AUTOSAR XML (schema 4-0-3)
standard types defined: Boolean, UInt16, UInt32, UInt8
package /AUTOSAR_Platform/DataConstrs
  range DC_Boolean: raw 0..1
  range DC_UInt16: raw 0..65535
  range DC_UInt8: raw 0..255
package /PATAC/MSM/ComponentTypes
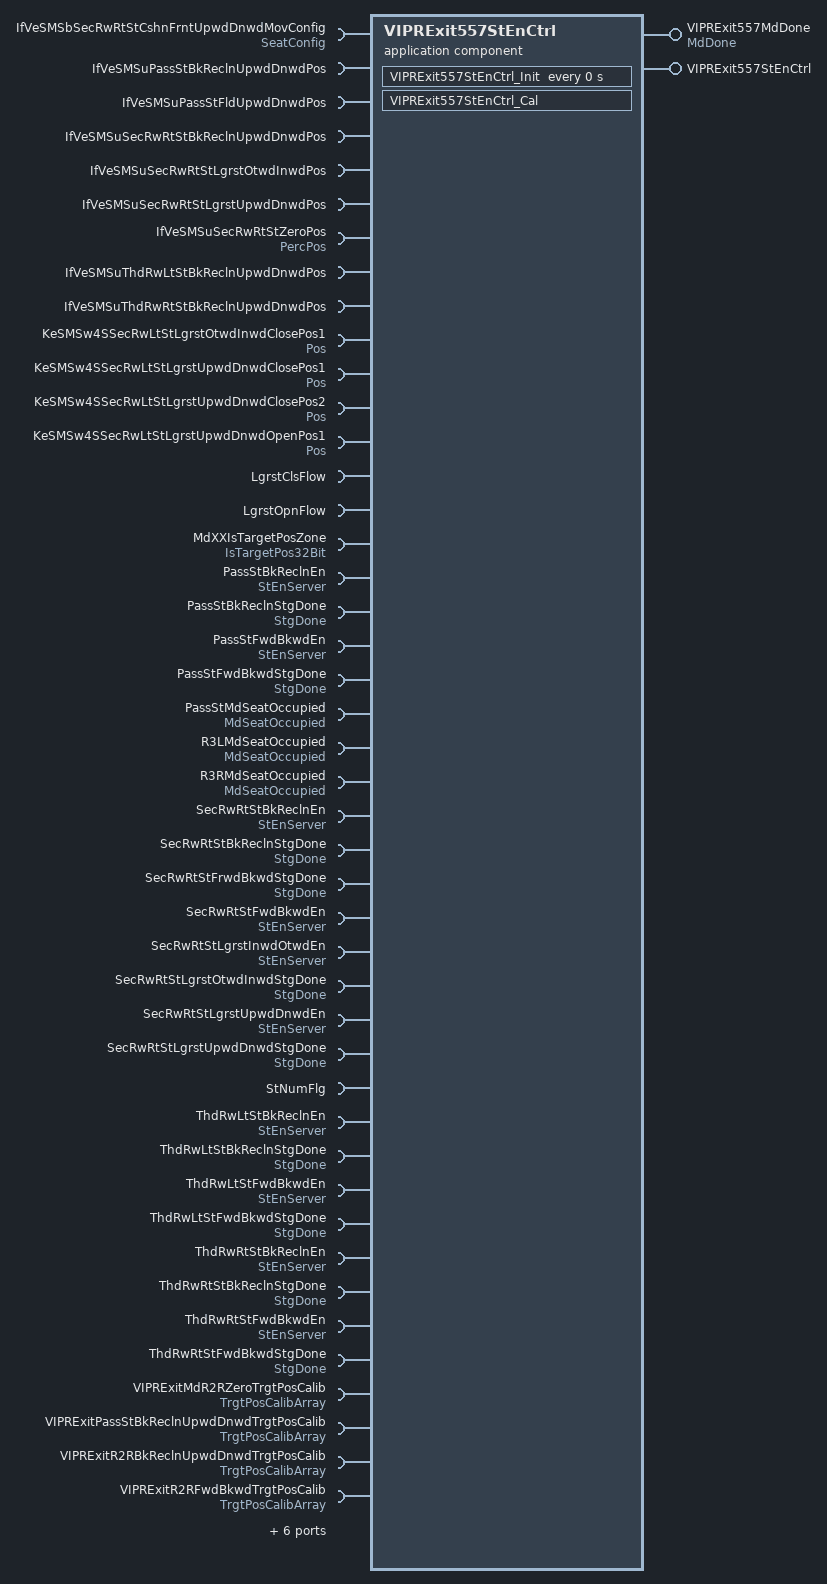
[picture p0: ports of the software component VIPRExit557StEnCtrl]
  application sw component type VIPRExit557StEnCtrl
    provide port VIPRExit557MdDone: nonqueued-sender-com-spec{data-element=MdDone/Val, init-value=0}, provided-interface=MdDone
    provide port VIPRExit557StEnCtrl: server-com-spec{operation=VIPRExit557StEnCtrl/Cal, queue-length=1}, provided-interface=VIPRExit557StEnCtrl
    50 x require port:
      IfVeSMSbSecRwRtStCshnFrntUpwdDnwdMovConfig: nonqueued-receiver-com-spec{data-element=SeatConfig/Val, filter=data-filter-type=ALWAYS, init-value=0}, required-interface=SeatConfig
      IfVeSMSuPassStBkReclnUpwdDnwdPos: nonqueued-receiver-com-spec{data-element=IfVeSMSuPassStBkReclnUpwdDnwdPos/Val, filter=data-filter-type=ALWAYS, init-value=0}, required-interface=IfVeSMSuPassStBkReclnUpwdDnwdPos
      IfVeSMSuPassStFldUpwdDnwdPos: nonqueued-receiver-com-spec{data-element=IfVeSMSuPassStFldUpwdDnwdPos/Val, filter=data-filter-type=ALWAYS, init-value=0}, required-interface=IfVeSMSuPassStFldUpwdDnwdPos
      IfVeSMSuSecRwRtStBkReclnUpwdDnwdPos: nonqueued-receiver-com-spec{data-element=IfVeSMSuSecRwRtStBkReclnUpwdDnwdPos/Val, filter=data-filter-type=ALWAYS, init-value=0}, required-interface=IfVeSMSuSecRwRtStBkReclnUpwdDnwdPos
      IfVeSMSuSecRwRtStLgrstOtwdInwdPos: nonqueued-receiver-com-spec{data-element=IfVeSMSuSecRwRtStLgrstOtwdInwdPos/Val, filter=data-filter-type=ALWAYS, init-value=0}, required-interface=IfVeSMSuSecRwRtStLgrstOtwdInwdPos
      IfVeSMSuSecRwRtStLgrstUpwdDnwdPos: nonqueued-receiver-com-spec{data-element=IfVeSMSuSecRwRtStLgrstUpwdDnwdPos/Val, filter=data-filter-type=ALWAYS, init-value=0}, required-interface=IfVeSMSuSecRwRtStLgrstUpwdDnwdPos
      IfVeSMSuSecRwRtStZeroPos: nonqueued-receiver-com-spec{data-element=PercPos/Val, filter=data-filter-type=ALWAYS, init-value=0}, required-interface=PercPos
      IfVeSMSuThdRwLtStBkReclnUpwdDnwdPos: nonqueued-receiver-com-spec{data-element=IfVeSMSuThdRwLtStBkReclnUpwdDnwdPos/Val, filter=data-filter-type=ALWAYS, init-value=0}, required-interface=IfVeSMSuThdRwLtStBkReclnUpwdDnwdPos
      IfVeSMSuThdRwRtStBkReclnUpwdDnwdPos: nonqueued-receiver-com-spec{data-element=IfVeSMSuThdRwRtStBkReclnUpwdDnwdPos/Val, filter=data-filter-type=ALWAYS, init-value=0}, required-interface=IfVeSMSuThdRwRtStBkReclnUpwdDnwdPos
      KeSMSw4SSecRwLtStLgrstOtwdInwdClosePos1: parameter-require-com-spec{init-value=0, parameter=Val}, required-interface=Pos
      KeSMSw4SSecRwLtStLgrstUpwdDnwdClosePos1: parameter-require-com-spec{init-value=0, parameter=Val}, required-interface=Pos
      KeSMSw4SSecRwLtStLgrstUpwdDnwdClosePos2: parameter-require-com-spec{init-value=0, parameter=Val}, required-interface=Pos
      KeSMSw4SSecRwLtStLgrstUpwdDnwdOpenPos1: parameter-require-com-spec{init-value=0, parameter=Val}, required-interface=Pos
      LgrstClsFlow: client-com-spec=LgrstClsFlow/Cal, required-interface=LgrstClsFlow
      LgrstOpnFlow: client-com-spec=LgrstOpnFlow/Cal, required-interface=LgrstOpnFlow
      MdXXIsTargetPosZone: nonqueued-receiver-com-spec{data-element=IsTargetPos32Bit/Val, filter=data-filter-type=ALWAYS, init-value=0}, required-interface=IsTargetPos32Bit
      PassStBkReclnEn: required-com-specs=[Clear, Get, Set], required-interface=StEnServer
      PassStBkReclnStgDone: nonqueued-receiver-com-spec{data-element=StgDone/Val, filter=data-filter-type=ALWAYS, init-value=0}, required-interface=StgDone
      PassStFwdBkwdEn: required-com-specs=[Clear, Get, Set], required-interface=StEnServer
      PassStFwdBkwdStgDone: nonqueued-receiver-com-spec{data-element=StgDone/Val, filter=data-filter-type=ALWAYS, init-value=0}, required-interface=StgDone
      PassStMdSeatOccupied: nonqueued-receiver-com-spec{data-element=MdSeatOccupied/Val, filter=data-filter-type=ALWAYS, init-value=0}, required-interface=MdSeatOccupied
      R3LMdSeatOccupied: nonqueued-receiver-com-spec{data-element=MdSeatOccupied/Val, filter=data-filter-type=ALWAYS, init-value=0}, required-interface=MdSeatOccupied
      R3RMdSeatOccupied: nonqueued-receiver-com-spec{data-element=MdSeatOccupied/Val, filter=data-filter-type=ALWAYS, init-value=0}, required-interface=MdSeatOccupied
      SecRwRtStBkReclnEn: required-com-specs=[Clear, Get, Set], required-interface=StEnServer
      SecRwRtStBkReclnStgDone: nonqueued-receiver-com-spec{data-element=StgDone/Val, filter=data-filter-type=ALWAYS, init-value=0}, required-interface=StgDone
      SecRwRtStFrwdBkwdStgDone: nonqueued-receiver-com-spec{data-element=StgDone/Val, filter=data-filter-type=ALWAYS, init-value=0}, required-interface=StgDone
      SecRwRtStFwdBkwdEn: required-com-specs=[Clear, Get, Set], required-interface=StEnServer
      SecRwRtStLgrstInwdOtwdEn: required-com-specs=[Clear, Get, Set], required-interface=StEnServer
      SecRwRtStLgrstOtwdInwdStgDone: nonqueued-receiver-com-spec{data-element=StgDone/Val, filter=data-filter-type=ALWAYS, init-value=0}, required-interface=StgDone
      SecRwRtStLgrstUpwdDnwdEn: required-com-specs=[Clear, Get, Set], required-interface=StEnServer
      SecRwRtStLgrstUpwdDnwdStgDone: nonqueued-receiver-com-spec{data-element=StgDone/Val, filter=data-filter-type=ALWAYS, init-value=0}, required-interface=StgDone
      StNumFlg: required-interface=StNumFlg
        required-com-specs:
          data-element=Is4s, filter=data-filter-type=ALWAYS, init-value=0
          data-element=Is6s, filter=data-filter-type=ALWAYS, init-value=0
          data-element=Is6s7s, filter=data-filter-type=ALWAYS, init-value=0
          data-element=Is7s, filter=data-filter-type=ALWAYS, init-value=0
      ThdRwLtStBkReclnEn: required-com-specs=[Clear, Get, Set], required-interface=StEnServer
      ThdRwLtStBkReclnStgDone: nonqueued-receiver-com-spec{data-element=StgDone/Val, filter=data-filter-type=ALWAYS, init-value=0}, required-interface=StgDone
      ThdRwLtStFwdBkwdEn: required-com-specs=[Clear, Get, Set], required-interface=StEnServer
      ThdRwLtStFwdBkwdStgDone: nonqueued-receiver-com-spec{data-element=StgDone/Val, filter=data-filter-type=ALWAYS, init-value=0}, required-interface=StgDone
      ThdRwRtStBkReclnEn: required-com-specs=[Clear, Get, Set], required-interface=StEnServer
      ThdRwRtStBkReclnStgDone: nonqueued-receiver-com-spec{data-element=StgDone/Val, filter=data-filter-type=ALWAYS, init-value=0}, required-interface=StgDone
      ThdRwRtStFwdBkwdEn: required-com-specs=[Clear, Get, Set], required-interface=StEnServer
      ThdRwRtStFwdBkwdStgDone: nonqueued-receiver-com-spec{data-element=StgDone/Val, filter=data-filter-type=ALWAYS, init-value=0}, required-interface=StgDone
      VIPRExitMdR2RZeroTrgtPosCalib: nonqueued-receiver-com-spec{data-element=TrgtPosArray, filter=data-filter-type=ALWAYS, init-value=[4095, 4095, 4095]}, required-interface=TrgtPosCalibArray
      VIPRExitPassStBkReclnUpwdDnwdTrgtPosCalib: nonqueued-receiver-com-spec{data-element=TrgtPosArray, filter=data-filter-type=ALWAYS, init-value=[4095, 4095, 4095]}, required-interface=TrgtPosCalibArray
      VIPRExitR2RBkReclnUpwdDnwdTrgtPosCalib: nonqueued-receiver-com-spec{data-element=TrgtPosArray, filter=data-filter-type=ALWAYS, init-value=[4095, 4095, 4095]}, required-interface=TrgtPosCalibArray
      VIPRExitR2RFwdBkwdTrgtPosCalib: nonqueued-receiver-com-spec{data-element=TrgtPosArray, filter=data-filter-type=ALWAYS, init-value=[4095, 4095, 4095]}, required-interface=TrgtPosCalibArray
      VIPRExitR2RLgrstInwdOtwdTrgtPosCalib: nonqueued-receiver-com-spec{data-element=TrgtPosArray, filter=data-filter-type=ALWAYS, init-value=[4095, 4095, 4095]}, required-interface=TrgtPosCalibArray
      VIPRExitR2RLgrstUpwdDnwdTrgtPosCalib: nonqueued-receiver-com-spec{data-element=TrgtPosArray, filter=data-filter-type=ALWAYS, init-value=[4095, 4095, 4095]}, required-interface=TrgtPosCalibArray
      VIPRExitR3LBkReclnUpwdDnwdTrgtPosCalib: nonqueued-receiver-com-spec{data-element=TrgtPosArray, filter=data-filter-type=ALWAYS, init-value=[4095, 4095, 4095]}, required-interface=TrgtPosCalibArray
      VIPRExitR3RBkReclnUpwdDnwdTrgtPosCalib: nonqueued-receiver-com-spec{data-element=TrgtPosArray, filter=data-filter-type=ALWAYS, init-value=[4095, 4095, 4095]}, required-interface=TrgtPosCalibArray
      ZeroREn: required-com-specs=[Clear, Get, Set], required-interface=StEnServer
      ZeroRStgDone: nonqueued-receiver-com-spec{data-element=StgDone/Val, filter=data-filter-type=ALWAYS, init-value=0}, required-interface=StgDone
    behavior VIPRExit557StEnCtrl_InternalBehavior
      operation invoked event OIT_VIPRExit557StEnCtrl_Cal_VIPRExit557StEnCtrl_Cal: start-on-event=VIPRExit557StEnCtrl_Cal, operation=VIPRExit557StEnCtrl.Cal
      timing event VIPRExit557StEnCtrl_InitEvent: start-on-event=VIPRExit557StEnCtrl_Init, period=0
      runnable VIPRExit557StEnCtrl_Cal
        data-receive-point-by-arguments:
          36 x access:
            REC_IfVeSMSbSecRwRtStCshnFrntUpwdDnwdMovConfig_Val: accessed-variable=IfVeSMSbSecRwRtStCshnFrntUpwdDnwdMovConfig.Val
            REC_IfVeSMSuPassStBkReclnUpwdDnwdPos_Val: accessed-variable=IfVeSMSuPassStBkReclnUpwdDnwdPos.Val
            REC_IfVeSMSuPassStFldUpwdDnwdPos_Val: accessed-variable=IfVeSMSuPassStFldUpwdDnwdPos.Val
            REC_IfVeSMSuSecRwRtStBkReclnUpwdDnwdPos_Val: accessed-variable=IfVeSMSuSecRwRtStBkReclnUpwdDnwdPos.Val
            REC_IfVeSMSuSecRwRtStLgrstOtwdInwdPos_Val: accessed-variable=IfVeSMSuSecRwRtStLgrstOtwdInwdPos.Val
            REC_IfVeSMSuSecRwRtStLgrstUpwdDnwdPos_Val: accessed-variable=IfVeSMSuSecRwRtStLgrstUpwdDnwdPos.Val
            REC_IfVeSMSuSecRwRtStZeroPos_Val: accessed-variable=IfVeSMSuSecRwRtStZeroPos.Val
            REC_IfVeSMSuThdRwLtStBkReclnUpwdDnwdPos_Val: accessed-variable=IfVeSMSuThdRwLtStBkReclnUpwdDnwdPos.Val
            REC_IfVeSMSuThdRwRtStBkReclnUpwdDnwdPos_Val: accessed-variable=IfVeSMSuThdRwRtStBkReclnUpwdDnwdPos.Val
            REC_MdXXIsTargetPosZone_Val: accessed-variable=MdXXIsTargetPosZone.Val
            REC_PassStBkReclnStgDone_Val: accessed-variable=PassStBkReclnStgDone.Val
            REC_PassStFwdBkwdStgDone_Val: accessed-variable=PassStFwdBkwdStgDone.Val
            REC_PassStMdSeatOccupied_Val: accessed-variable=PassStMdSeatOccupied.Val
            REC_R3LMdSeatOccupied_Val: accessed-variable=R3LMdSeatOccupied.Val
            REC_R3RMdSeatOccupied_Val: accessed-variable=R3RMdSeatOccupied.Val
            REC_SecRwRtStBkReclnStgDone_Val: accessed-variable=SecRwRtStBkReclnStgDone.Val
            REC_SecRwRtStFrwdBkwdStgDone_Val: accessed-variable=SecRwRtStFrwdBkwdStgDone.Val
            REC_SecRwRtStLgrstOtwdInwdStgDone_Val: accessed-variable=SecRwRtStLgrstOtwdInwdStgDone.Val
            REC_SecRwRtStLgrstUpwdDnwdStgDone_Val: accessed-variable=SecRwRtStLgrstUpwdDnwdStgDone.Val
            REC_StNumFlg_Is4s: accessed-variable=StNumFlg.Is4s
            REC_StNumFlg_Is6s: accessed-variable=StNumFlg.Is6s
            REC_StNumFlg_Is6s7s: accessed-variable=StNumFlg.Is6s7s
            REC_StNumFlg_Is7s: accessed-variable=StNumFlg.Is7s
            REC_ThdRwLtStBkReclnStgDone_Val: accessed-variable=ThdRwLtStBkReclnStgDone.Val
            REC_ThdRwLtStFwdBkwdStgDone_Val: accessed-variable=ThdRwLtStFwdBkwdStgDone.Val
            REC_ThdRwRtStBkReclnStgDone_Val: accessed-variable=ThdRwRtStBkReclnStgDone.Val
            REC_ThdRwRtStFwdBkwdStgDone_Val: accessed-variable=ThdRwRtStFwdBkwdStgDone.Val
            REC_VIPRExitMdR2RZeroTrgtPosCalib_TrgtPosArray: accessed-variable=VIPRExitMdR2RZeroTrgtPosCalib.TrgtPosArray
            REC_VIPRExitPassStBkReclnUpwdDnwdTrgtPosCalib_TrgtPosArray: accessed-variable=VIPRExitPassStBkReclnUpwdDnwdTrgtPosCalib.TrgtPosArray
            REC_VIPRExitR2RBkReclnUpwdDnwdTrgtPosCalib_TrgtPosArray: accessed-variable=VIPRExitR2RBkReclnUpwdDnwdTrgtPosCalib.TrgtPosArray
            REC_VIPRExitR2RFwdBkwdTrgtPosCalib_TrgtPosArray: accessed-variable=VIPRExitR2RFwdBkwdTrgtPosCalib.TrgtPosArray
            REC_VIPRExitR2RLgrstInwdOtwdTrgtPosCalib_TrgtPosArray: accessed-variable=VIPRExitR2RLgrstInwdOtwdTrgtPosCalib.TrgtPosArray
            REC_VIPRExitR2RLgrstUpwdDnwdTrgtPosCalib_TrgtPosArray: accessed-variable=VIPRExitR2RLgrstUpwdDnwdTrgtPosCalib.TrgtPosArray
            REC_VIPRExitR3LBkReclnUpwdDnwdTrgtPosCalib_TrgtPosArray: accessed-variable=VIPRExitR3LBkReclnUpwdDnwdTrgtPosCalib.TrgtPosArray
            REC_VIPRExitR3RBkReclnUpwdDnwdTrgtPosCalib_TrgtPosArray: accessed-variable=VIPRExitR3RBkReclnUpwdDnwdTrgtPosCalib.TrgtPosArray
            REC_ZeroRStgDone_Val: accessed-variable=ZeroRStgDone.Val
        data-send-points:
          access SEND_VIPRExit557MdDone_Val: accessed-variable=VIPRExit557MdDone.Val
        4 x parameter access:
          PA_KeSMSw4SSecRwLtStLgrstOtwdInwdClosePos1_Val: accessed-parameter=KeSMSw4SSecRwLtStLgrstOtwdInwdClosePos1.Val
          PA_KeSMSw4SSecRwLtStLgrstUpwdDnwdClosePos1_Val: accessed-parameter=KeSMSw4SSecRwLtStLgrstUpwdDnwdClosePos1.Val
          PA_KeSMSw4SSecRwLtStLgrstUpwdDnwdClosePos2_Val: accessed-parameter=KeSMSw4SSecRwLtStLgrstUpwdDnwdClosePos2.Val
          PA_KeSMSw4SSecRwLtStLgrstUpwdDnwdOpenPos1_Val: accessed-parameter=KeSMSw4SSecRwLtStLgrstUpwdDnwdOpenPos1.Val
        24 x sync call, all with timeout=0:
          SC_LgrstClsFlow_Cal: operation=LgrstClsFlow.Cal
          SC_LgrstOpnFlow_Cal: operation=LgrstOpnFlow.Cal
          SC_PassStBkReclnEn_Clear: operation=PassStBkReclnEn.Clear
          SC_PassStBkReclnEn_Set: operation=PassStBkReclnEn.Set
          SC_PassStFwdBkwdEn_Clear: operation=PassStFwdBkwdEn.Clear
          SC_PassStFwdBkwdEn_Set: operation=PassStFwdBkwdEn.Set
          SC_SecRwRtStBkReclnEn_Clear: operation=SecRwRtStBkReclnEn.Clear
          SC_SecRwRtStBkReclnEn_Set: operation=SecRwRtStBkReclnEn.Set
          SC_SecRwRtStFwdBkwdEn_Clear: operation=SecRwRtStFwdBkwdEn.Clear
          SC_SecRwRtStFwdBkwdEn_Set: operation=SecRwRtStFwdBkwdEn.Set
          SC_SecRwRtStLgrstInwdOtwdEn_Clear: operation=SecRwRtStLgrstInwdOtwdEn.Clear
          SC_SecRwRtStLgrstInwdOtwdEn_Set: operation=SecRwRtStLgrstInwdOtwdEn.Set
          SC_SecRwRtStLgrstUpwdDnwdEn_Clear: operation=SecRwRtStLgrstUpwdDnwdEn.Clear
          SC_SecRwRtStLgrstUpwdDnwdEn_Set: operation=SecRwRtStLgrstUpwdDnwdEn.Set
          SC_ThdRwLtStBkReclnEn_Clear: operation=ThdRwLtStBkReclnEn.Clear
          SC_ThdRwLtStBkReclnEn_Set: operation=ThdRwLtStBkReclnEn.Set
          SC_ThdRwLtStFwdBkwdEn_Clear: operation=ThdRwLtStFwdBkwdEn.Clear
          SC_ThdRwLtStFwdBkwdEn_Set: operation=ThdRwLtStFwdBkwdEn.Set
          SC_ThdRwRtStBkReclnEn_Clear: operation=ThdRwRtStBkReclnEn.Clear
          SC_ThdRwRtStBkReclnEn_Set: operation=ThdRwRtStBkReclnEn.Set
          SC_ThdRwRtStFwdBkwdEn_Clear: operation=ThdRwRtStFwdBkwdEn.Clear
          SC_ThdRwRtStFwdBkwdEn_Set: operation=ThdRwRtStFwdBkwdEn.Set
          SC_ZeroREn_Clear: operation=ZeroREn.Clear
          SC_ZeroREn_Set: operation=ZeroREn.Set
      runnable VIPRExit557StEnCtrl_Init
        4 x parameter access:
          PA_KeSMSw4SSecRwLtStLgrstOtwdInwdClosePos1_Val: accessed-parameter=KeSMSw4SSecRwLtStLgrstOtwdInwdClosePos1.Val
          PA_KeSMSw4SSecRwLtStLgrstUpwdDnwdClosePos1_Val: accessed-parameter=KeSMSw4SSecRwLtStLgrstUpwdDnwdClosePos1.Val
          PA_KeSMSw4SSecRwLtStLgrstUpwdDnwdClosePos2_Val: accessed-parameter=KeSMSw4SSecRwLtStLgrstUpwdDnwdClosePos2.Val
          PA_KeSMSw4SSecRwLtStLgrstUpwdDnwdOpenPos1_Val: accessed-parameter=KeSMSw4SSecRwLtStLgrstUpwdDnwdOpenPos1.Val
  swc implementation VIPRExit557StEnCtrl_Implementation: behavior=VIPRExit557StEnCtrl_InternalBehavior
    code-descriptors:
      code Default: artifact-descriptors=autosar-engineering-object={short-label=Default, category=SWSRC}
package /PATAC/MSM/ModeAdjust/CalPortInterface
  parameter interface Pos
    parameter data prototype Val: sw-calibration-access=READ-WRITE, type=UInt16
package /PATAC/MSM/ModeAdjust/DataType
  impl type TrgtPosCalibArray: category=ARRAY, sw-calibration-access=READ-ONLY, type-emitter=RTE  # 0:pos 1:max 2:min
    element Element: array-size=3, array-size-semantics=FIXED-SIZE, implementation-data-type=UInt16, invalid-value=0
package /PATAC/MSM/ModeAdjust/PortInterface
  4 x client server interface:
    LgrstClsFlow
      operation Cal
        13 x arg, all with server-argument-impl-policy=USE-ARGUMENT-TYPE:
          LgrstUpwdDnwdPos: type=UInt16, direction=IN
          LgrstOtwdInwdPos: type=UInt16, direction=IN
          FtUpwdDnwdPos: type=UInt16, direction=IN
          CloseDnwdPos1: type=UInt16, direction=IN
          CloseDnwdPos2: type=UInt16, direction=IN
          CloseOtwdPos1: type=UInt16, direction=IN
          LgrstInwdStgDone: type=Implementation/Boolean, direction=IN
          LgrstUpwdStgDone: type=Implementation/Boolean, direction=IN
          FtrstStgDone: type=Implementation/Boolean, direction=IN
          Failflg: type=Implementation/Boolean, direction=OUT
          LgrstInwdOtwdEn: type=Implementation/Boolean, direction=OUT
          LgrstUpwdDnwdEn: type=Implementation/Boolean, direction=OUT
          FtrstEn: type=Implementation/Boolean, direction=OUT
    LgrstOpnFlow
      operation Cal
        9 x arg, all with server-argument-impl-policy=USE-ARGUMENT-TYPE:
          LgrstUpwdDnwdPos: type=UInt16, direction=IN
          LgrstUpwdDnwdOpenPos1: type=UInt16, direction=IN
          LgrstUpwdStgDone: type=Implementation/Boolean, direction=IN
          FtrstStgDone: type=Implementation/Boolean, direction=IN
          LgrstInwdStgDone: type=Implementation/Boolean, direction=IN
          Failflg: type=Implementation/Boolean, direction=OUT
          LgrstInwdOtwdEn: type=Implementation/Boolean, direction=OUT
          LgrstUpwdDnwdEn: type=Implementation/Boolean, direction=OUT
          FtrstEn: type=Implementation/Boolean, direction=OUT
    StEnServer
      operation Clear
        arg data: type=UInt8, direction=IN, server-argument-impl-policy=USE-ARGUMENT-TYPE
      operation Get
        arg data: type=UInt32, direction=OUT, server-argument-impl-policy=USE-ARGUMENT-TYPE
      operation Set
        arg data: type=UInt8, direction=IN, server-argument-impl-policy=USE-ARGUMENT-TYPE
    VIPRExit557StEnCtrl
      operation Cal
        arg FirstTrig: type=DataTypes/Boolean, direction=IN, server-argument-impl-policy=USE-ARGUMENT-TYPE
  8 x sender receiver interface:
    IfVeSMSuPassStFldUpwdDnwdPos: invalidation-policy{data-element=IfVeSMSuPassStFldUpwdDnwdPos/Val, handle-invalid=DONT-INVALIDATE}
      data Val: type=UInt16
    IsTargetPos32Bit: invalidation-policy{data-element=IsTargetPos32Bit/Val, handle-invalid=DONT-INVALIDATE}
      data Val: type=UInt32
    MdDone: invalidation-policy{data-element=MdDone/Val, handle-invalid=DONT-INVALIDATE}
      data Val: type=UInt8
    MdSeatOccupied: invalidation-policy{data-element=MdSeatOccupied/Val, handle-invalid=DONT-INVALIDATE}
      data Val: type=Implementation/Boolean
    PercPos: invalidation-policy{data-element=PercPos/Val, handle-invalid=DONT-INVALIDATE}
      data Val: type=UInt16
    StgDone: invalidation-policy{data-element=StgDone/Val, handle-invalid=DONT-INVALIDATE}
      data Val: type=Implementation/Boolean
    StNumFlg
      4 x data, all with type=Implementation/Boolean:
        Is4s
        Is6s
        Is6s7s
        Is7s
      invalidation-policys:
        data-element=Is4s, handle-invalid=DONT-INVALIDATE
        data-element=Is6s, handle-invalid=DONT-INVALIDATE
        data-element=Is6s7s, handle-invalid=DONT-INVALIDATE
        data-element=Is7s, handle-invalid=DONT-INVALIDATE
    TrgtPosCalibArray: invalidation-policy{data-element=TrgtPosArray, handle-invalid=DONT-INVALIDATE}
      data TrgtPosArray: type=TrgtPosCalibArray  # 0:Pos 1:Max 2:Min
package /PATAC/MSM/PortInterfaces
  7 x sender receiver interface:
    IfVeSMSuPassStBkReclnUpwdDnwdPos: invalidation-policy{data-element=IfVeSMSuPassStBkReclnUpwdDnwdPos/Val, handle-invalid=DONT-INVALIDATE}
      data Val: type=UInt16
    IfVeSMSuSecRwRtStBkReclnUpwdDnwdPos: invalidation-policy{data-element=IfVeSMSuSecRwRtStBkReclnUpwdDnwdPos/Val, handle-invalid=DONT-INVALIDATE}
      data Val: type=UInt16
    IfVeSMSuSecRwRtStLgrstOtwdInwdPos: invalidation-policy{data-element=IfVeSMSuSecRwRtStLgrstOtwdInwdPos/Val, handle-invalid=DONT-INVALIDATE}
      data Val: type=UInt16
    IfVeSMSuSecRwRtStLgrstUpwdDnwdPos: invalidation-policy{data-element=IfVeSMSuSecRwRtStLgrstUpwdDnwdPos/Val, handle-invalid=DONT-INVALIDATE}
      data Val: type=UInt16
    IfVeSMSuThdRwLtStBkReclnUpwdDnwdPos: invalidation-policy{data-element=IfVeSMSuThdRwLtStBkReclnUpwdDnwdPos/Val, handle-invalid=DONT-INVALIDATE}
      data Val: type=UInt16
    IfVeSMSuThdRwRtStBkReclnUpwdDnwdPos: invalidation-policy{data-element=IfVeSMSuThdRwRtStBkReclnUpwdDnwdPos/Val, handle-invalid=DONT-INVALIDATE}
      data Val: type=UInt16
    SeatConfig: invalidation-policy{data-element=SeatConfig/Val, handle-invalid=DONT-INVALIDATE}
      data Val: type=Implementation/Boolean
